# ADuCM363 register map
Vendor: Analog Devices Inc.; Series: ADuCM36x; File version: 0.1
CPU: CM3 r2p1, little endian, no MPU, no FPU, 3 interrupt priority bits
Registers are 16-bit, read-write, no defined reset value unless marked. A register's access mark holds for its fields unless they carry their own. Offsets are from the block's base; [hi:lo] are bit positions; {n}, {i} and the like mark numbered series.

## ADI_T1 — Timer 1
Base 0x40000400
0x00 T1LD — 16-bit load value
  [15:0] VALUE range 0x00000000..0x0000FFFF — Load value
0x04 T1VAL ro — 16-bit timer value, read only.
  [15:0] VALUE range 0x00000000..0x0000FFFF — Current value
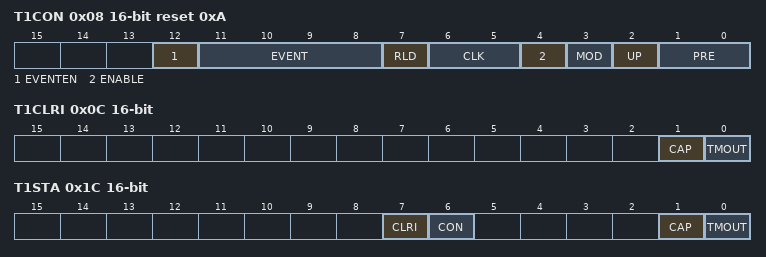
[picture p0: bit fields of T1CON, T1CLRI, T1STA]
0x08 T1CON reset 0xA (reset mask 0x0) — Control Register
  [12] EVENTEN — Enable time capture of an event
    0=DIS; 1=EN
  [11:8] EVENT — Event Select, selects 1 of the available events.
    0=COM; 1=T0 (- Timer0); 2=SPI0; 3=SPI1; 4=I2CS; 5=I2CM; 6=DMAERR; 7=DMADONE; 8=EXT1; 9=EXT2; 10=EXT3; 11=PWMTRIP; 12=PWM0; 13=PWM1; 14=PWM2; 15=ADC0
  [7] RLD — Timer reload on write to clear register
    0=DIS; 1=EN
  [6:5] CLK — Clock Select
    0=UCLK (- System Clock); 1=PCLK (- Peripheral clock); 2=LFOSC (- Internal 32 kHz Oscillator); 3=LFXTAL (- External 32 kHz crystal)
  [4] ENABLE
    0=DIS; 1=EN
  [3] MOD — Mode
    0=FREERUN; 1=PERIODIC
  [2] UP — Count-up
    0=DIS; 1=EN
  [1:0] PRE — Prescaler
    0=DIV1; 1=DIV16; 2=DIV256; 3=DIV32768 (- If the selected clock source is UCLK then this setting results in a prescaler of 4.)
0x0C T1CLRI — Clear interrupt register
  [1] CAP — Clear captured event interrupt
    1=CLR
  [0] TMOUT — Clear timeout interrupt
    1=CLR
0x10 T1CAP ro — Capture Register
  [15:0] VALUE range 0x00000000..0x0000FFFF — Capture value
0x1C T1STA ro — Status Register
  [all] fields
    0=CLR; 1=SET
  [7] CLRI — Value updated in the timer clock domain
  [6] CON — Ready to receive commands
  [1] CAP — Capture event pending
  [0] TMOUT — Time out event occurred

## ADI_PWM — Pulse Width Modulation
Base 0x40001000
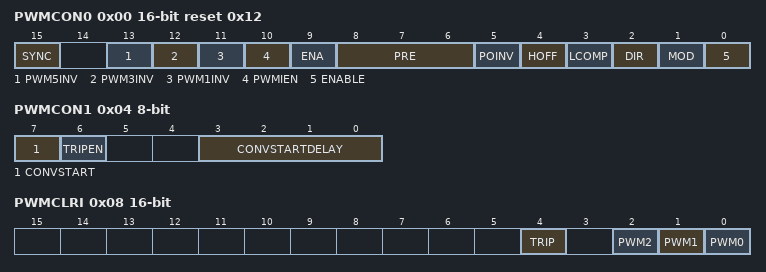
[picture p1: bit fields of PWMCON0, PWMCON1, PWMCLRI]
0x00 PWMCON0 reset 0x12 (reset mask 0x0) — PWM Control register
  [15] SYNC — PWM Synchronization
    0=DIS; 1=EN
  [13] PWM5INV — Inversion of PWM output
    0=DIS; 1=EN
  [12] PWM3INV — Inversion of PWM output
    0=DIS; 1=EN
  [11] PWM1INV — Inversion of PWM output
    0=DIS; 1=EN
  [10] PWMIEN — Enables PWM interrupts
    0=DIS; 1=EN
  [9] ENA — enable PWM outputs
    0=DIS; 1=EN
  [8:6] PRE range 0x00000000..0x00000007 — PWM Clock Prescaler
  [5] POINV — Invert all PWM outputs
    0=DIS; 1=EN
  [4] HOFF — High Side Off
    0=DIS; 1=EN
  [3] LCOMP — Load Compare Registers
    0=DIS; 1=EN
  [2] DIR — Direction Control
    0=DIS; 1=EN
  [1] MOD — Enables H-Bridge Mode
    0=DIS; 1=EN
  [0] ENABLE — Enables all PWM outputs
    0=DIS; 1=EN
0x04 PWMCON1 8-bit — Trip control register
  [7] CONVSTART — Enable adc conversion start from pwm
    0=DIS; 1=EN
  [6] TRIPEN — Enable PWM trip functionality
    0=DIS; 1=EN
  [3:0] CONVSTARTDELAY range 0x00000000..0x0000000F — ADC conversion start delay configuration
0x08 PWMCLRI wo — PWM interrupt clear. Write to this register clears the latched PWM interrupt.
  [all] fields
    0=DIS; 1=EN
  [4] TRIP — Clear the latched trip interrupt
  [2] PWM2 — Clear the latched PWM2 interrupt
  [1] PWM1 — Clear the latched PWM1 interrupt
  [0] PWM0 — Clear the latched PWM0 interrupt
{0x10+0x10*i} PWM{i}COM0 (i=0..2) — Compare Register 0 for PWM{2i} and PWM{2i+1}
{0x14+0x10*i} PWM{i}COM1 (i=0..2) — Compare Register 1 for PWM{2i} and PWM{2i+1}
{0x18+0x10*i} PWM{i}COM2 (i=0..2) — Compare Register 2 for PWM{2i} and PWM{2i+1}
{0x1C+0x10*i} PWM{i}LEN (i=0..2) — Period Value register for PWM{2i} and PWM{2i+1}

## ADI_PWRCTL — Power Management Unit
Base 0x40002400
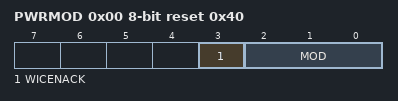
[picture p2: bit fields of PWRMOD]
0x00 PWRMOD 8-bit reset 0x40 (reset mask 0x0) — Power modes register
  [3] WICENACK — For Deepsleep mode only
    0=DIS; 1=EN
  [2:0] MOD — Power Mode
    0=FULLACTIVE; 1=MCUHALT; 2=PERHALT; 3=SYSHALT; 4=TOTALHALT; 5=HIBERNATE
0x04 PWRKEY — Key protection for the PWRMOD register.
  [15:0] VALUE — Key value
    0x4859=KEY1; 0xF27B=KEY2
